# eeprom register map
Vendor: Texas Instruments
Peripheral module from a debugger description file (folder sc4ce290ncpz).
Registers are 32-bit, read-write, no defined reset value unless marked. A register's access mark holds for its fields unless they carry their own. Offsets are as the file gives them; lines under a group give offsets from that group; [hi:lo] are bit positions; {n}, {i} and the like mark numbered series; 'fields as' and 'values as' point back to an identical list; <NAME> marks a mode.

## EEPROM — EEPROM register offsets
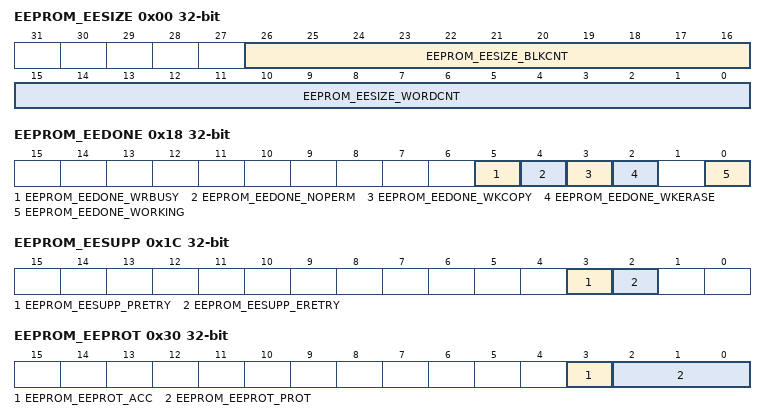
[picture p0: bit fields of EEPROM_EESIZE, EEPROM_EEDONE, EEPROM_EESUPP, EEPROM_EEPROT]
0x00 EEPROM_EESIZE ro — EEPROM Size Information
  [26:16] EEPROM_EESIZE_BLKCNT — Number of 16-Word Blocks
  [15:0] EEPROM_EESIZE_WORDCNT — Number of 32-Bit Words
0x04 EEPROM_EEBLOCK — EEPROM Current Block
  [15:0] EEPROM_EEBLOCK_BLOCK — Current Block
0x08 EEPROM_EEOFFSET — EEPROM Current Offset
  [3:0] EEPROM_EEOFFSET_OFFSET — Current Address Offset
0x10 EEPROM_EERDWR — EEPROM Read-Write
  [31:0] EEPROM_EERDWR_VALUE — EEPROM Read or Write Data
0x14 EEPROM_EERDWRINC — EEPROM Read-Write with Increment
  [31:0] EEPROM_EERDWRINC_VALUE — EEPROM Read or Write Data with Increment
0x18 EEPROM_EEDONE ro — EEPROM Done Status
  [5] EEPROM_EEDONE_WRBUSY — Write Busy
  [4] EEPROM_EEDONE_NOPERM — Write Without Permission
  [3] EEPROM_EEDONE_WKCOPY — Working on a Copy
  [2] EEPROM_EEDONE_WKERASE — Working on an Erase
  [0] EEPROM_EEDONE_WORKING — EEPROM Working
0x1C EEPROM_EESUPP — EEPROM Support Control and Status
  [3] EEPROM_EESUPP_PRETRY — Programming Must Be Retried
  [2] EEPROM_EESUPP_ERETRY — Erase Must Be Retried
0x20 EEPROM_EEUNLOCK — EEPROM Unlock
  [31:0] EEPROM_EEUNLOCK_UNLOCK
0x30 EEPROM_EEPROT — EEPROM Protection
  [3] EEPROM_EEPROT_ACC — Access Control
  [2:0] EEPROM_EEPROT_PROT — Protection Control
    0=EEPROM_EEPROT_PROT_RWNPW (This setting is the default. If there is no password, the block is not protected and is readable and writable); 1=EEPROM_EEPROT_PROT_RWPW (If there is a password, the block is readable or writable only when unlocked); 2=EEPROM_EEPROT_PROT_RONPW (If there is no password, the block is readable, not writable)
{0x34+4i} EEPROM_EEPASS{i} (i=0..2) — EEPROM Password
  [31:0] EEPROM_EEPASS{i}_PASS — Password
0x40 EEPROM_EEINT — EEPROM Interrupt
  [0] EEPROM_EEINT_INT — Interrupt Enable
0x50 EEPROM_EEHIDE0 — EEPROM Block Hide 0
  [31:1] EEPROM_EEHIDE0_HN — Hide Block
0x54 EEPROM_EEHIDE1 — EEPROM Block Hide 1
  [31:0] EEPROM_EEHIDE1_HN — Hide Block
0x58 EEPROM_EEHIDE2 — EEPROM Block Hide 2
  [31:0] EEPROM_EEHIDE2_HN — Hide Block
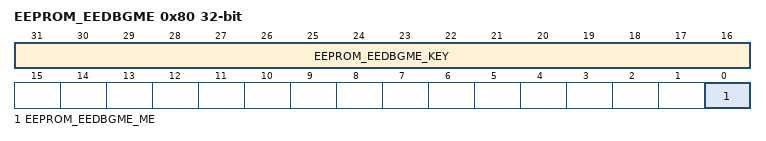
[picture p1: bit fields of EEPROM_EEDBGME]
0x80 EEPROM_EEDBGME — EEPROM Debug Mass Erase
  [31:16] EEPROM_EEDBGME_KEY — Erase Key
  [0] EEPROM_EEDBGME_ME — Mass Erase
0xFC0 EEPROM_PP ro — EEPROM Peripheral Properties
  [15:0] EEPROM_PP_SIZE — EEPROM Size
    0=64 bytes of EEPROM; 1=128 bytes of EEPROM; 3=256 bytes of EEPROM; 7=512 bytes of EEPROM; 15=EEPROM_PP_SIZE_1K (1 KB of EEPROM); 31=EEPROM_PP_SIZE_2K (2 KB of EEPROM); 63=EEPROM_PP_SIZE_3K (3 KB of EEPROM); 127=EEPROM_PP_SIZE_4K (4 KB of EEPROM); 255=EEPROM_PP_SIZE_5K (5 KB of EEPROM); 0x1FF=EEPROM_PP_SIZE_6K (6 KB of EEPROM)
